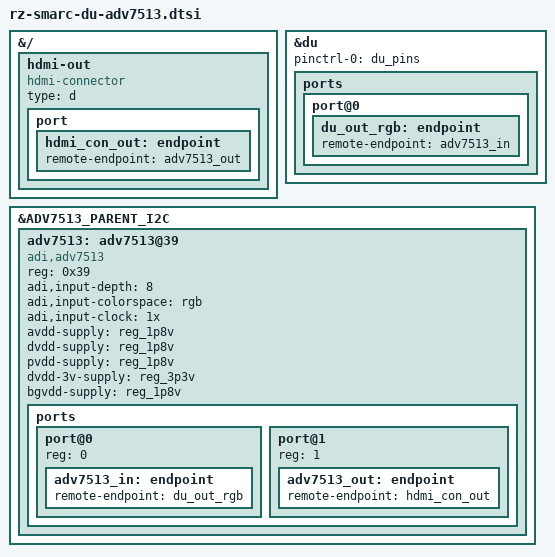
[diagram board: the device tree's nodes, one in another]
// SPDX-License-Identifier: GPL-2.0
/*
 * Common Device Tree for the RZ/G2UL SMARC EVK (and alike EVKs) with
 * ADV7513 transmitter connected to DU enabled.
 *
 * Copyright (C) 2024 Renesas Electronics Corp.
 */

&{/} {
	hdmi-out {
		compatible = "hdmi-connector";
		type = "d";

		port {
			hdmi_con_out: endpoint {
				remote-endpoint = <&adv7513_out>;
			};
		};
	};
};

&du {
	pinctrl-0 = <&du_pins>;
	pinctrl-names = "default";

	status = "okay";

	ports {
		port@0 {
			du_out_rgb: endpoint {
				remote-endpoint = <&adv7513_in>;
			};
		};
	};
};

&ADV7513_PARENT_I2C {
	#address-cells = <1>;
	#size-cells = <0>;

	adv7513: adv7513@39 {
		compatible = "adi,adv7513";
		reg = <0x39>;

		adi,input-depth = <8>;
		adi,input-colorspace = "rgb";
		adi,input-clock = "1x";

		avdd-supply = <&reg_1p8v>;
		dvdd-supply = <&reg_1p8v>;
		pvdd-supply = <&reg_1p8v>;
		dvdd-3v-supply = <&reg_3p3v>;
		bgvdd-supply = <&reg_1p8v>;

		ports {
			#address-cells = <1>;
			#size-cells = <0>;

			port@0 {
				reg = <0>;

				adv7513_in: endpoint {
					remote-endpoint = <&du_out_rgb>;
				};
			};

			port@1 {
				reg = <1>;

				adv7513_out: endpoint {
					remote-endpoint = <&hdmi_con_out>;
				};
			};
		};
	};
};
